# STM32L052 register map
File version: 1.0
CPU: CM0+ r0p0, little endian, MPU, no FPU, 4 interrupt priority bits
Registers are 32-bit, read-write, reset 0x0 unless marked. A register's access mark holds for its fields unless they carry their own. Offsets are from the block's base; [hi:lo] are bit positions; lines under a group give offsets from that group; {n}, {i} and the like mark numbered series; 'fields as' and 'values as' point back to an identical list.

## TSC — Touch sensing controller
Base 0x40024000
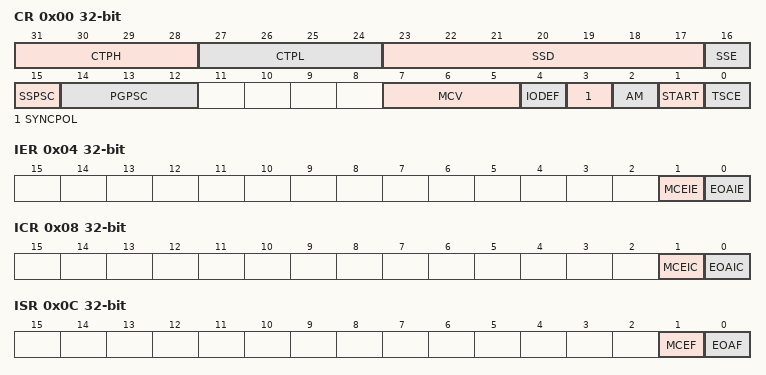
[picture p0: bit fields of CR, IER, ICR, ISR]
0x00 CR — control register
  [31:28] CTPH — Charge transfer pulse high
  [27:24] CTPL — Charge transfer pulse low
  [23:17] SSD — Spread spectrum deviation
  [16] SSE — Spread spectrum enable
  [15] SSPSC — Spread spectrum prescaler
  [14:12] PGPSC — pulse generator prescaler
  [7:5] MCV — Max count value
  [4] IODEF — I/O Default mode
  [3] SYNCPOL — Synchronization pin polarity
  [2] AM — Acquisition mode
  [1] START — Start a new acquisition
  [0] TSCE — Touch sensing controller enable
0x04 IER — interrupt enable register
  [1] MCEIE — Max count error interrupt enable
  [0] EOAIE — End of acquisition interrupt enable
0x08 ICR — interrupt clear register
  [1] MCEIC — Max count error interrupt clear
  [0] EOAIC — End of acquisition interrupt clear
0x0C ISR — interrupt status register
  [1] MCEF — Max count error flag
  [0] EOAF — End of acquisition flag
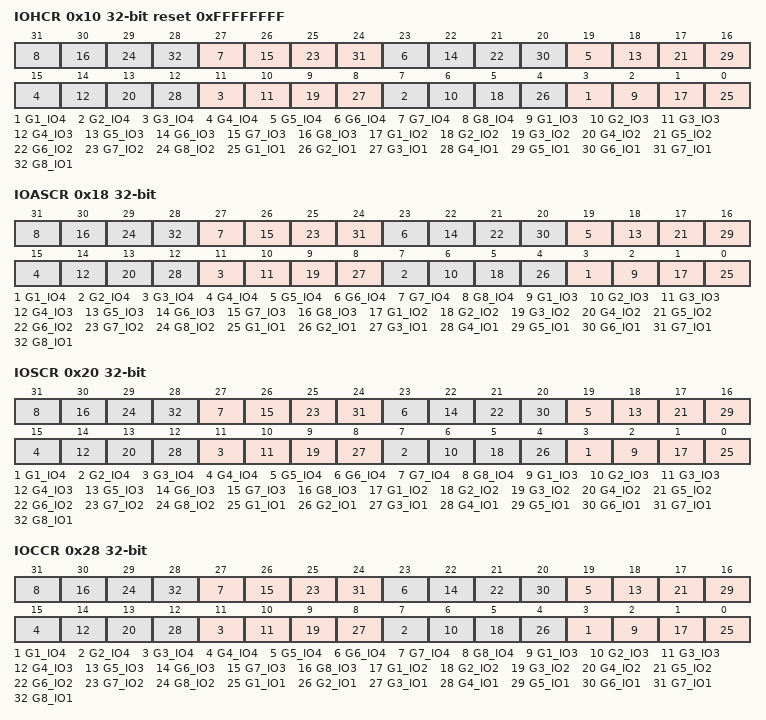
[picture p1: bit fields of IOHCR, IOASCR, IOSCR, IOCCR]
0x10 IOHCR reset 0xFFFFFFFF — I/O hysteresis control register
  [4n-1] G{n}_IO4 (n=1..8), [4n-2] G{n}_IO3 (n=1..8), [4n-3] G{n}_IO2 (n=1..8), [4n-4] G{n}_IO1 (n=1..8)
0x18 IOASCR — I/O analog switch control register
  fields as IOHCR
0x20 IOSCR — I/O sampling control register
  fields as IOHCR
0x28 IOCCR — I/O channel control register
  fields as IOHCR
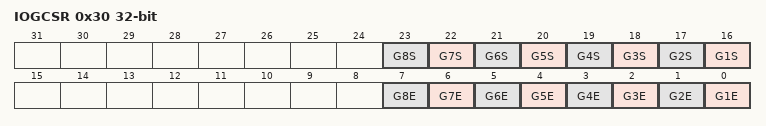
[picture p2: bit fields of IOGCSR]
0x30 IOGCSR access per field — I/O group control status register
  [n+15] G{n}S ro (n=1..8) — Analog I/O group x status
  [n-1] G{n}E rw (n=1..8) — Analog I/O group x enable
{0x30+4i} IOG{i}CR ro (i=1..8) — I/O group x counter register
  [13:0] CNT — Counter value

## IWDG — Independent watchdog
Base 0x40003000
0x00 KR wo — Key register
  [15:0] KEY — Key value (write only, read 0x0000)
0x04 PR — Prescaler register
  [2:0] PR — Prescaler divider
0x08 RLR reset 0xFFF — Reload register
  [11:0] RL — Watchdog counter reload value
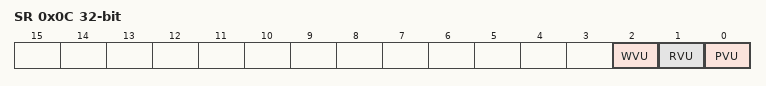
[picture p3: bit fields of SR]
0x0C SR ro — Status register
  [2] WVU — Watchdog counter window value update
  [1] RVU — Watchdog counter reload value update
  [0] PVU — Watchdog prescaler value update
0x10 WINR reset 0xFFF — Window register
  [11:0] WIN — Watchdog counter window value

## WWDG — System window watchdog
Base 0x40002C00
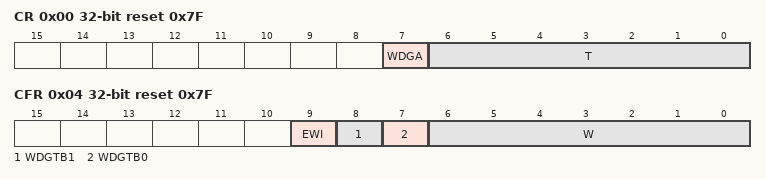
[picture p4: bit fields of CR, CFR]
0x00 CR reset 0x7F — Control register
  [7] WDGA — Activation bit
  [6:0] T — 7-bit counter (MSB to LSB)
0x04 CFR reset 0x7F — Configuration register
  [9] EWI — Early wakeup interrupt
  [8] WDGTB1 — Timer base
  [7] WDGTB0
  [6:0] W — 7-bit window value
0x08 SR — Status register
  [0] EWIF — Early wakeup interrupt flag

## CRS — Clock recovery system
Base 0x40006C00
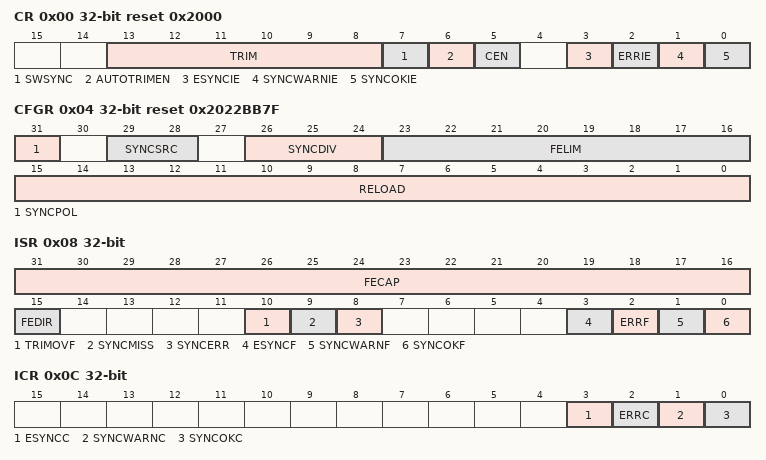
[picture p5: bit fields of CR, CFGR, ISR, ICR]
0x00 CR reset 0x2000 — control register
  [13:8] TRIM — HSI48 oscillator smooth trimming
  [7] SWSYNC — Generate software SYNC event
  [6] AUTOTRIMEN — Automatic trimming enable
  [5] CEN — Frequency error counter enable
  [3] ESYNCIE — Expected SYNC interrupt enable
  [2] ERRIE — Synchronization or trimming error interrupt enable
  [1] SYNCWARNIE — SYNC warning interrupt enable
  [0] SYNCOKIE — SYNC event OK interrupt enable
0x04 CFGR reset 0x2022BB7F — configuration register
  [31] SYNCPOL — SYNC polarity selection
  [29:28] SYNCSRC — SYNC signal source selection
  [26:24] SYNCDIV — SYNC divider
  [23:16] FELIM — Frequency error limit
  [15:0] RELOAD — Counter reload value
0x08 ISR ro — interrupt and status register
  [31:16] FECAP — Frequency error capture
  [15] FEDIR — Frequency error direction
  [10] TRIMOVF — Trimming overflow or underflow
  [9] SYNCMISS — SYNC missed
  [8] SYNCERR — SYNC error
  [3] ESYNCF — Expected SYNC flag
  [2] ERRF — Error flag
  [1] SYNCWARNF — SYNC warning flag
  [0] SYNCOKF — SYNC event OK flag
0x0C ICR — interrupt flag clear register
  [3] ESYNCC — Expected SYNC clear flag
  [2] ERRC — Error clear flag
  [1] SYNCWARNC — SYNC warning clear flag
  [0] SYNCOKC — SYNC event OK clear flag
